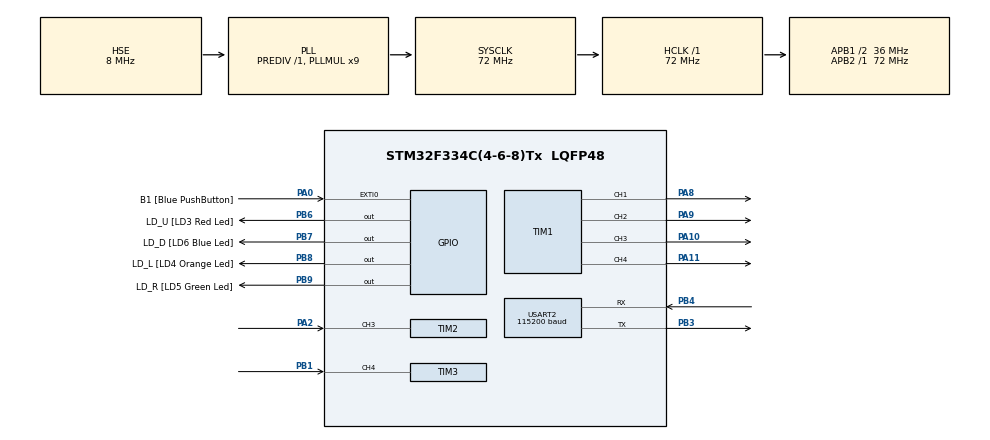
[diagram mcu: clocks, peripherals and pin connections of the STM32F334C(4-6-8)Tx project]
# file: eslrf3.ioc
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Dma.Request0=TIM1_UP
Dma.Request1=USART2_RX
Dma.Request2=USART2_TX
Dma.Request3=TIM2_CH3
Dma.Request4=TIM3_CH4/UP
Dma.TIM1_UP.0.Direction=DMA_MEMORY_TO_PERIPH
Dma.TIM1_UP.0.Instance=DMA1_Channel5
Dma.TIM1_UP.0.MemDataAlignment=DMA_MDATAALIGN_HALFWORD
Dma.TIM1_UP.0.MemInc=DMA_MINC_ENABLE
Dma.TIM1_UP.0.Mode=DMA_NORMAL
Dma.TIM1_UP.0.PeriphDataAlignment=DMA_PDATAALIGN_HALFWORD
Dma.TIM1_UP.0.PeriphInc=DMA_PINC_DISABLE
Dma.TIM1_UP.0.Priority=DMA_PRIORITY_LOW
Dma.TIM2_CH3.3.Direction=DMA_PERIPH_TO_MEMORY
Dma.TIM2_CH3.3.Instance=DMA1_Channel1
Dma.TIM2_CH3.3.MemDataAlignment=DMA_MDATAALIGN_WORD
Dma.TIM2_CH3.3.MemInc=DMA_MINC_ENABLE
Dma.TIM2_CH3.3.Mode=DMA_CIRCULAR
Dma.TIM2_CH3.3.PeriphDataAlignment=DMA_PDATAALIGN_WORD
Dma.TIM2_CH3.3.PeriphInc=DMA_PINC_DISABLE
Dma.TIM2_CH3.3.Priority=DMA_PRIORITY_LOW
Dma.TIM3_CH4/UP.4.Direction=DMA_PERIPH_TO_MEMORY
Dma.TIM3_CH4/UP.4.Instance=DMA1_Channel3
Dma.TIM3_CH4/UP.4.MemDataAlignment=DMA_MDATAALIGN_WORD
Dma.TIM3_CH4/UP.4.MemInc=DMA_MINC_ENABLE
Dma.TIM3_CH4/UP.4.Mode=DMA_CIRCULAR
Dma.TIM3_CH4/UP.4.PeriphDataAlignment=DMA_PDATAALIGN_WORD
Dma.TIM3_CH4/UP.4.PeriphInc=DMA_PINC_DISABLE
Dma.TIM3_CH4/UP.4.Priority=DMA_PRIORITY_LOW
Dma.USART2_RX.1.Direction=DMA_PERIPH_TO_MEMORY
Dma.USART2_RX.1.Instance=DMA1_Channel6
Dma.USART2_RX.1.MemDataAlignment=DMA_MDATAALIGN_BYTE
Dma.USART2_RX.1.MemInc=DMA_MINC_ENABLE
Dma.USART2_RX.1.Mode=DMA_CIRCULAR
Dma.USART2_RX.1.PeriphDataAlignment=DMA_PDATAALIGN_BYTE
Dma.USART2_RX.1.PeriphInc=DMA_PINC_DISABLE
Dma.USART2_RX.1.Priority=DMA_PRIORITY_LOW
Dma.USART2_TX.2.Direction=DMA_MEMORY_TO_PERIPH
Dma.USART2_TX.2.Instance=DMA1_Channel7
Dma.USART2_TX.2.MemDataAlignment=DMA_MDATAALIGN_BYTE
Dma.USART2_TX.2.MemInc=DMA_MINC_ENABLE
Dma.USART2_TX.2.Mode=DMA_NORMAL
Dma.USART2_TX.2.PeriphDataAlignment=DMA_PDATAALIGN_BYTE
Dma.USART2_TX.2.PeriphInc=DMA_PINC_DISABLE
Dma.USART2_TX.2.Priority=DMA_PRIORITY_LOW
Mcu.Family=STM32F3
Mcu.Name=STM32F334C(4-6-8)Tx
Mcu.Package=LQFP48
NVIC.DMA1_Channel1_IRQn=true\:0\:0\:false\:false\:true\:false\:true
NVIC.DMA1_Channel3_IRQn=true\:0\:0\:false\:false\:true\:false\:true
NVIC.DMA1_Channel5_IRQn=true\:0\:0\:false\:false\:true\:false\:true
NVIC.DMA1_Channel6_IRQn=true\:0\:0\:false\:false\:true\:false\:true
NVIC.DMA1_Channel7_IRQn=true\:0\:0\:false\:false\:true\:false\:true
NVIC.PriorityGroup=NVIC_PRIORITYGROUP_0
NVIC.USART2_IRQn=true\:0\:0\:false\:false\:true\:true\:true
PA0.GPIO_Label=B1 [Blue PushButton]
PA0.GPIO_ModeDefaultEXTI=GPIO_MODE_EVT_RISING
PA0.GPIO_PuPd=GPIO_NOPULL
PA0.Signal=GPXTI0
PA10.GPIO_Speed=GPIO_SPEED_FREQ_HIGH
PA10.Signal=S_TIM1_CH3
PA11.GPIO_Speed=GPIO_SPEED_FREQ_HIGH
PA11.Signal=S_TIM1_CH4
PA13.GPIO_Label=SWDIO
PA13.Mode=Serial_Wire
PA13.Signal=SYS_JTMS-SWDIO
PA14.GPIO_Label=SWCLK
PA14.Mode=Serial_Wire
PA14.Signal=SYS_JTCK-SWCLK
PA2.GPIO_PuPd=GPIO_PULLUP
PA2.GPIO_Speed=GPIO_SPEED_FREQ_HIGH
PA2.Signal=S_TIM2_CH3
PA8.GPIO_Speed=GPIO_SPEED_FREQ_HIGH
PA8.Signal=S_TIM1_CH1
PA9.GPIO_Speed=GPIO_SPEED_FREQ_HIGH
PA9.Signal=S_TIM1_CH2
PB1.GPIO_PuPd=GPIO_PULLUP
PB1.GPIO_Speed=GPIO_SPEED_FREQ_HIGH
PB1.Signal=S_TIM3_CH4
PB3.GPIO_PuPd=GPIO_PULLUP
PB3.GPIO_Speed=GPIO_SPEED_FREQ_HIGH
PB3.Mode=Asynchronous
PB3.Signal=USART2_TX
PB4.GPIO_PuPd=GPIO_PULLUP
PB4.GPIO_Speed=GPIO_SPEED_FREQ_HIGH
PB4.Mode=Asynchronous
PB4.Signal=USART2_RX
PB6.GPIO_FM6=__NULL
PB6.GPIO_Label=LD_U [LD3 Red Led]
PB6.GPIO_ModeDefaultOutputPP=GPIO_MODE_OUTPUT_PP
PB6.GPIO_PuPd=GPIO_NOPULL
PB6.GPIO_Speed=GPIO_SPEED_FREQ_LOW
PB6.Signal=GPIO_Output
PB7.GPIO_FM7=__NULL
PB7.GPIO_Label=LD_D [LD6 Blue Led]
PB7.GPIO_ModeDefaultOutputPP=GPIO_MODE_OUTPUT_PP
PB7.GPIO_PuPd=GPIO_NOPULL
PB7.GPIO_Speed=GPIO_SPEED_FREQ_LOW
PB7.Signal=GPIO_Output
PB8.GPIO_FM8=__NULL
PB8.GPIO_Label=LD_L [LD4 Orange Led]
PB8.GPIO_ModeDefaultOutputPP=GPIO_MODE_OUTPUT_PP
PB8.GPIO_PuPd=GPIO_NOPULL
PB8.GPIO_Speed=GPIO_SPEED_FREQ_LOW
PB8.Signal=GPIO_Output
PB9.GPIO_FM9=__NULL
PB9.GPIO_Label=LD_R [LD5 Green Led]
PB9.GPIO_ModeDefaultOutputPP=GPIO_MODE_OUTPUT_PP
PB9.GPIO_PuPd=GPIO_NOPULL
PB9.GPIO_Speed=GPIO_SPEED_FREQ_LOW
PB9.Signal=GPIO_Output
PF0\ /\ OSC_IN.GPIO_Label=PF0-OSC_IN
PF0\ /\ OSC_IN.Mode=HSE-External-Clock-Source
PF0\ /\ OSC_IN.Signal=RCC_OSC_IN
PF1\ /\ OSC_OUT.GPIO_Label=PF1_OSC_OUT
PF1\ /\ OSC_OUT.Signal=RCC_OSC_OUT
ProjectManager.HeapSize=0x2000
ProjectManager.StackSize=0x1000
ProjectManager.TargetToolchain=MDK-ARM V5.32
RCC.AHBFreq_Value=72000000
RCC.APB1CLKDivider=RCC_HCLK_DIV2
RCC.APB1Freq_Value=36000000
RCC.APB1TimFreq_Value=72000000
RCC.APB2Freq_Value=72000000
RCC.APB2TimFreq_Value=72000000
RCC.CortexFreq_Value=72000000
RCC.HCLKFreq_Value=72000000
RCC.HSE_VALUE=8000000
RCC.HSI_VALUE=8000000
RCC.LSE_VALUE=32768
RCC.PLLMUL=RCC_PLL_MUL9
RCC.PLLSourceVirtual=RCC_PLLSOURCE_HSE
RCC.SYSCLKFreq_VALUE=72000000
RCC.SYSCLKSourceVirtual=RCC_SYSCLKSOURCE_PLLCLK
SH.S_TIM1_CH1.0=TIM1_CH1,PWM Generation1 CH1
SH.S_TIM1_CH2.0=TIM1_CH2,PWM Generation2 CH2
SH.S_TIM1_CH3.0=TIM1_CH3,PWM Generation3 CH3
SH.S_TIM1_CH4.0=TIM1_CH4,PWM Generation4 CH4
SH.S_TIM2_CH3.0=TIM2_CH3,Input_Capture3_from_TI3
SH.S_TIM3_CH4.0=TIM3_CH4,Input_Capture4_from_TI4
TIM1.Channel-PWM\ Generation1\ CH1=TIM_CHANNEL_1
TIM1.Channel-PWM\ Generation2\ CH2=TIM_CHANNEL_2
TIM1.Channel-PWM\ Generation3\ CH3=TIM_CHANNEL_3
TIM1.Channel-PWM\ Generation4\ CH4=TIM_CHANNEL_4
TIM1.TIM_MasterOutputTrigger=TIM_TRGO_ENABLE
TIM1.TIM_MasterSlaveMode=TIM_MASTERSLAVEMODE_ENABLE
TIM2.Channel-Input_Capture3_from_TI3=TIM_CHANNEL_3
TIM2.ICPolarity_CH3=TIM_INPUTCHANNELPOLARITY_BOTHEDGE
TIM2.Period=65535
TIM3.Channel-Input_Capture4_from_TI4=TIM_CHANNEL_4
TIM3.ICPolarity_CH4=TIM_INPUTCHANNELPOLARITY_BOTHEDGE
USART2.BaudRate=115200
USART2.VirtualMode-Asynchronous=VM_ASYNC
VP_TIM2_VS_ClockSourceITR.Mode=TriggerSource_ITR0
VP_TIM2_VS_ControllerModeTrigger.Mode=Trigger Mode
VP_TIM3_VS_ClockSourceITR.Mode=TriggerSource_ITR0
VP_TIM3_VS_ControllerModeTrigger.Mode=Trigger Mode
board=STM32F3348-DISCO

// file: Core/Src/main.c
/* USER CODE BEGIN Header */
/**
  ******************************************************************************
  * @file           : main.c
  * @brief          : Main program body
  ******************************************************************************
  * @attention
  *
  * <h2><center>&copy; Copyright (c) 2021 STMicroelectronics.
  * All rights reserved.</center></h2>
  *
  * This software component is licensed by ST under BSD 3-Clause license,
  * the "License"; You may not use this file except in compliance with the
  * License. You may obtain a copy of the License at:
  *                        opensource.org/licenses/BSD-3-Clause
  *
  ******************************************************************************
  */
/* USER CODE END Header */
#include "main.h"

/* USER CODE BEGIN Includes */
#include "io.h"
#include "misc.h"
#include "proc.h"
/* USER CODE END Includes */

/* USER CODE BEGIN PTD */
void 		app(void);
/* USER CODE END PTD */

TIM_HandleTypeDef htim1;
TIM_HandleTypeDef htim2;
TIM_HandleTypeDef htim3;
DMA_HandleTypeDef hdma_tim1_up;
DMA_HandleTypeDef hdma_tim2_ch3;
DMA_HandleTypeDef hdma_tim3_ch4_up;

UART_HandleTypeDef huart2;
DMA_HandleTypeDef hdma_usart2_rx;
DMA_HandleTypeDef hdma_usart2_tx;

void SystemClock_Config(void);
static void MX_GPIO_Init(void);
static void MX_DMA_Init(void);
static void MX_TIM1_Init(void);
static void MX_USART2_UART_Init(void);
static void MX_TIM2_Init(void);
static void MX_TIM3_Init(void);

/* USER CODE BEGIN 0 */
_io *com;
/* USER CODE END 0 */

int main(void)
{

  /* MCU Configuration--------------------------------------------------------*/

  /* Reset of all peripherals, Initializes the Flash interface and the Systick. */
  HAL_Init();

  /* Configure the system clock */
  SystemClock_Config();

  /* Initialize all configured peripherals */
  MX_GPIO_Init();
  MX_DMA_Init();
  MX_TIM1_Init();
  MX_USART2_UART_Init();
  MX_TIM2_Init();
  MX_TIM3_Init();
  /* USER CODE BEGIN 2 */
	com=newCom(&huart2, 128,128);
	_stdio(com);
  /* USER CODE END 2 */

  /* Infinite loop */
  /* USER CODE BEGIN WHILE */

  /* USER CODE END 2 */

  /* Infinite loop */
  /* USER CODE BEGIN WHILE */
  while (1)
  {
		_proc_loop();
		app();
    /* USER CODE END WHILE */

  }
}

void SystemClock_Config(void)
{
  RCC_OscInitTypeDef RCC_OscInitStruct = {0};
  RCC_ClkInitTypeDef RCC_ClkInitStruct = {0};
  RCC_PeriphCLKInitTypeDef PeriphClkInit = {0};

  /** Initializes the RCC Oscillators according to the specified parameters
  * in the RCC_OscInitTypeDef structure.
  */
  RCC_OscInitStruct.OscillatorType = RCC_OSCILLATORTYPE_HSE;
  RCC_OscInitStruct.HSEState = RCC_HSE_BYPASS;
  RCC_OscInitStruct.HSEPredivValue = RCC_HSE_PREDIV_DIV1;
  RCC_OscInitStruct.HSIState = RCC_HSI_ON;
  RCC_OscInitStruct.PLL.PLLState = RCC_PLL_ON;
  RCC_OscInitStruct.PLL.PLLSource = RCC_PLLSOURCE_HSE;
  RCC_OscInitStruct.PLL.PLLMUL = RCC_PLL_MUL9;
  if (HAL_RCC_OscConfig(&RCC_OscInitStruct) != HAL_OK)
  {
    Error_Handler();
  }
  /** Initializes the CPU, AHB and APB buses clocks
  */
  RCC_ClkInitStruct.ClockType = RCC_CLOCKTYPE_HCLK|RCC_CLOCKTYPE_SYSCLK
                              |RCC_CLOCKTYPE_PCLK1|RCC_CLOCKTYPE_PCLK2;
  RCC_ClkInitStruct.SYSCLKSource = RCC_SYSCLKSOURCE_PLLCLK;
  RCC_ClkInitStruct.AHBCLKDivider = RCC_SYSCLK_DIV1;
  RCC_ClkInitStruct.APB1CLKDivider = RCC_HCLK_DIV2;
  RCC_ClkInitStruct.APB2CLKDivider = RCC_HCLK_DIV1;

  if (HAL_RCC_ClockConfig(&RCC_ClkInitStruct, FLASH_LATENCY_2) != HAL_OK)
  {
    Error_Handler();
  }
  PeriphClkInit.PeriphClockSelection = RCC_PERIPHCLK_TIM1;
  PeriphClkInit.Tim1ClockSelection = RCC_TIM1CLK_HCLK;
  if (HAL_RCCEx_PeriphCLKConfig(&PeriphClkInit) != HAL_OK)
  {
    Error_Handler();
  }
}

static void MX_TIM1_Init(void)
{

  TIM_MasterConfigTypeDef sMasterConfig = {0};
  TIM_OC_InitTypeDef sConfigOC = {0};
  TIM_BreakDeadTimeConfigTypeDef sBreakDeadTimeConfig = {0};

  htim1.Instance = TIM1;
  htim1.Init.Prescaler = 0;
  htim1.Init.CounterMode = TIM_COUNTERMODE_UP;
  htim1.Init.Period = 65535;
  htim1.Init.ClockDivision = TIM_CLOCKDIVISION_DIV1;
  htim1.Init.RepetitionCounter = 0;
  htim1.Init.AutoReloadPreload = TIM_AUTORELOAD_PRELOAD_DISABLE;
  if (HAL_TIM_PWM_Init(&htim1) != HAL_OK)
  {
    Error_Handler();
  }
  sMasterConfig.MasterOutputTrigger = TIM_TRGO_ENABLE;
  sMasterConfig.MasterOutputTrigger2 = TIM_TRGO2_RESET;
  sMasterConfig.MasterSlaveMode = TIM_MASTERSLAVEMODE_ENABLE;
  if (HAL_TIMEx_MasterConfigSynchronization(&htim1, &sMasterConfig) != HAL_OK)
  {
    Error_Handler();
  }
  sConfigOC.OCMode = TIM_OCMODE_PWM1;
  sConfigOC.Pulse = 0;
  sConfigOC.OCPolarity = TIM_OCPOLARITY_HIGH;
  sConfigOC.OCNPolarity = TIM_OCNPOLARITY_HIGH;
  sConfigOC.OCFastMode = TIM_OCFAST_DISABLE;
  sConfigOC.OCIdleState = TIM_OCIDLESTATE_RESET;
  sConfigOC.OCNIdleState = TIM_OCNIDLESTATE_RESET;
  if (HAL_TIM_PWM_ConfigChannel(&htim1, &sConfigOC, TIM_CHANNEL_1) != HAL_OK)
  {
    Error_Handler();
  }
  if (HAL_TIM_PWM_ConfigChannel(&htim1, &sConfigOC, TIM_CHANNEL_2) != HAL_OK)
  {
    Error_Handler();
  }
  if (HAL_TIM_PWM_ConfigChannel(&htim1, &sConfigOC, TIM_CHANNEL_3) != HAL_OK)
  {
    Error_Handler();
  }
  if (HAL_TIM_PWM_ConfigChannel(&htim1, &sConfigOC, TIM_CHANNEL_4) != HAL_OK)
  {
    Error_Handler();
  }
  sBreakDeadTimeConfig.OffStateRunMode = TIM_OSSR_DISABLE;
  sBreakDeadTimeConfig.OffStateIDLEMode = TIM_OSSI_DISABLE;
  sBreakDeadTimeConfig.LockLevel = TIM_LOCKLEVEL_OFF;
  sBreakDeadTimeConfig.DeadTime = 0;
  sBreakDeadTimeConfig.BreakState = TIM_BREAK_DISABLE;
  sBreakDeadTimeConfig.BreakPolarity = TIM_BREAKPOLARITY_HIGH;
  sBreakDeadTimeConfig.BreakFilter = 0;
  sBreakDeadTimeConfig.Break2State = TIM_BREAK2_DISABLE;
  sBreakDeadTimeConfig.Break2Polarity = TIM_BREAK2POLARITY_HIGH;
  sBreakDeadTimeConfig.Break2Filter = 0;
  sBreakDeadTimeConfig.AutomaticOutput = TIM_AUTOMATICOUTPUT_DISABLE;
  if (HAL_TIMEx_ConfigBreakDeadTime(&htim1, &sBreakDeadTimeConfig) != HAL_OK)
  {
    Error_Handler();
  }
  HAL_TIM_MspPostInit(&htim1);

}

static void MX_TIM2_Init(void)
{

  TIM_SlaveConfigTypeDef sSlaveConfig = {0};
  TIM_MasterConfigTypeDef sMasterConfig = {0};
  TIM_IC_InitTypeDef sConfigIC = {0};

  htim2.Instance = TIM2;
  htim2.Init.Prescaler = 0;
  htim2.Init.CounterMode = TIM_COUNTERMODE_UP;
  htim2.Init.Period = 65535;
  htim2.Init.ClockDivision = TIM_CLOCKDIVISION_DIV1;
  htim2.Init.AutoReloadPreload = TIM_AUTORELOAD_PRELOAD_DISABLE;
  if (HAL_TIM_Base_Init(&htim2) != HAL_OK)
  {
    Error_Handler();
  }
  if (HAL_TIM_IC_Init(&htim2) != HAL_OK)
  {
    Error_Handler();
  }
  sSlaveConfig.SlaveMode = TIM_SLAVEMODE_TRIGGER;
  sSlaveConfig.InputTrigger = TIM_TS_ITR0;
  if (HAL_TIM_SlaveConfigSynchro(&htim2, &sSlaveConfig) != HAL_OK)
  {
    Error_Handler();
  }
  sMasterConfig.MasterOutputTrigger = TIM_TRGO_RESET;
  sMasterConfig.MasterSlaveMode = TIM_MASTERSLAVEMODE_DISABLE;
  if (HAL_TIMEx_MasterConfigSynchronization(&htim2, &sMasterConfig) != HAL_OK)
  {
    Error_Handler();
  }
  sConfigIC.ICPolarity = TIM_INPUTCHANNELPOLARITY_BOTHEDGE;
  sConfigIC.ICSelection = TIM_ICSELECTION_DIRECTTI;
  sConfigIC.ICPrescaler = TIM_ICPSC_DIV1;
  sConfigIC.ICFilter = 0;
  if (HAL_TIM_IC_ConfigChannel(&htim2, &sConfigIC, TIM_CHANNEL_3) != HAL_OK)
  {
    Error_Handler();
  }

}

static void MX_TIM3_Init(void)
{

  TIM_SlaveConfigTypeDef sSlaveConfig = {0};
  TIM_MasterConfigTypeDef sMasterConfig = {0};
  TIM_IC_InitTypeDef sConfigIC = {0};

  htim3.Instance = TIM3;
  htim3.Init.Prescaler = 0;
  htim3.Init.CounterMode = TIM_COUNTERMODE_UP;
  htim3.Init.Period = 65535;
  htim3.Init.ClockDivision = TIM_CLOCKDIVISION_DIV1;
  htim3.Init.AutoReloadPreload = TIM_AUTORELOAD_PRELOAD_DISABLE;
  if (HAL_TIM_Base_Init(&htim3) != HAL_OK)
  {
    Error_Handler();
  }
  if (HAL_TIM_IC_Init(&htim3) != HAL_OK)
  {
    Error_Handler();
  }
  sSlaveConfig.SlaveMode = TIM_SLAVEMODE_TRIGGER;
  sSlaveConfig.InputTrigger = TIM_TS_ITR0;
  if (HAL_TIM_SlaveConfigSynchro(&htim3, &sSlaveConfig) != HAL_OK)
  {
    Error_Handler();
  }
  sMasterConfig.MasterOutputTrigger = TIM_TRGO_RESET;
  sMasterConfig.MasterSlaveMode = TIM_MASTERSLAVEMODE_DISABLE;
  if (HAL_TIMEx_MasterConfigSynchronization(&htim3, &sMasterConfig) != HAL_OK)
  {
    Error_Handler();
  }
  sConfigIC.ICPolarity = TIM_INPUTCHANNELPOLARITY_BOTHEDGE;
  sConfigIC.ICSelection = TIM_ICSELECTION_DIRECTTI;
  sConfigIC.ICPrescaler = TIM_ICPSC_DIV1;
  sConfigIC.ICFilter = 0;
  if (HAL_TIM_IC_ConfigChannel(&htim3, &sConfigIC, TIM_CHANNEL_4) != HAL_OK)
  {
    Error_Handler();
  }

}

static void MX_USART2_UART_Init(void)
{

  huart2.Instance = USART2;
  huart2.Init.BaudRate = 115200;
  huart2.Init.WordLength = UART_WORDLENGTH_8B;
  huart2.Init.StopBits = UART_STOPBITS_1;
  huart2.Init.Parity = UART_PARITY_NONE;
  huart2.Init.Mode = UART_MODE_TX_RX;
  huart2.Init.HwFlowCtl = UART_HWCONTROL_NONE;
  huart2.Init.OverSampling = UART_OVERSAMPLING_16;
  huart2.Init.OneBitSampling = UART_ONE_BIT_SAMPLE_DISABLE;
  huart2.AdvancedInit.AdvFeatureInit = UART_ADVFEATURE_NO_INIT;
  if (HAL_UART_Init(&huart2) != HAL_OK)
  {
    Error_Handler();
  }

}

static void MX_DMA_Init(void)
{

  /* DMA controller clock enable */
  __HAL_RCC_DMA1_CLK_ENABLE();

  /* DMA interrupt init */
  /* DMA1_Channel1_IRQn interrupt configuration */
  HAL_NVIC_SetPriority(DMA1_Channel1_IRQn, 0, 0);
  HAL_NVIC_EnableIRQ(DMA1_Channel1_IRQn);
  /* DMA1_Channel3_IRQn interrupt configuration */
  HAL_NVIC_SetPriority(DMA1_Channel3_IRQn, 0, 0);
  HAL_NVIC_EnableIRQ(DMA1_Channel3_IRQn);
  /* DMA1_Channel5_IRQn interrupt configuration */
  HAL_NVIC_SetPriority(DMA1_Channel5_IRQn, 0, 0);
  HAL_NVIC_EnableIRQ(DMA1_Channel5_IRQn);
  /* DMA1_Channel6_IRQn interrupt configuration */
  HAL_NVIC_SetPriority(DMA1_Channel6_IRQn, 0, 0);
  HAL_NVIC_EnableIRQ(DMA1_Channel6_IRQn);
  /* DMA1_Channel7_IRQn interrupt configuration */
  HAL_NVIC_SetPriority(DMA1_Channel7_IRQn, 0, 0);
  HAL_NVIC_EnableIRQ(DMA1_Channel7_IRQn);

}

static void MX_GPIO_Init(void)
{
  GPIO_InitTypeDef GPIO_InitStruct = {0};

  /* GPIO Ports Clock Enable */
  __HAL_RCC_GPIOF_CLK_ENABLE();
  __HAL_RCC_GPIOA_CLK_ENABLE();
  __HAL_RCC_GPIOB_CLK_ENABLE();

  /*Configure GPIO pin Output Level */
  HAL_GPIO_WritePin(GPIOB, LD_U_Pin|LD_D_Pin|LD_L_Pin|LD_R_Pin, GPIO_PIN_RESET);

  /*Configure GPIO pin : B1_Pin */
  GPIO_InitStruct.Pin = B1_Pin;
  GPIO_InitStruct.Mode = GPIO_MODE_EVT_RISING;
  GPIO_InitStruct.Pull = GPIO_NOPULL;
  HAL_GPIO_Init(B1_GPIO_Port, &GPIO_InitStruct);

  /*Configure GPIO pins : LD_U_Pin LD_D_Pin LD_L_Pin LD_R_Pin */
  GPIO_InitStruct.Pin = LD_U_Pin|LD_D_Pin|LD_L_Pin|LD_R_Pin;
  GPIO_InitStruct.Mode = GPIO_MODE_OUTPUT_PP;
  GPIO_InitStruct.Pull = GPIO_NOPULL;
  GPIO_InitStruct.Speed = GPIO_SPEED_FREQ_LOW;
  HAL_GPIO_Init(GPIOB, &GPIO_InitStruct);

}

void Error_Handler(void)
{
  __disable_irq();
  while (1)
  {
  }
}

/************************ (C) COPYRIGHT STMicroelectronics *****END OF FILE****/
